# platform_designer_hps_system_hps_0_hps register map
Vendor: default_vendor.com; File version: 0.0
Registers are 32-bit, read-write, reset 0x0 unless marked. A register's access mark holds for its fields unless they carry their own. Offsets are from the block's base; [hi:lo] are bit positions; 'fields as' and 'values as' point back to an identical list.

## l4wd0 — Registers in the L4 Watchdog module
Base 0xFFD02000
Same registers: l4wd1 0xFFD03000
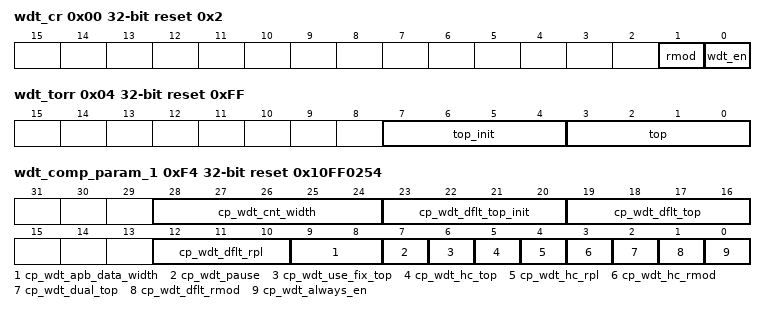
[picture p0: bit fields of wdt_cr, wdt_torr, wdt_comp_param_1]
0x00 wdt_cr reset 0x2 — Contains fields that control operating functions.
  [1] rmod — Selects the output response generated to a timeout.
    0=rst; 1=irqrst
  [0] wdt_en — This bit is used to enable and disable the watchdog. When disabled, the counter does not decrement. Thus, no interrupts or warm reset requests are generated. Once this bit has been enabled, it can only be cleared only by resetting the watchdog.
    0=disabled; 1=enabled
0x04 wdt_torr reset 0xFF — Contains fields that determine the watchdog timeout.
  [7:4] top_init — Used to select the timeout period that the watchdog counter restarts from for the first counter restart (kick). This register should be written after reset and before the watchdog is enabled. A change of the TOP_INIT is seen only once the watchdog has been enabled, and any change after the first kick is not seen as subsequent kicks use the period specified by the TOP bits. The timeout period (in clocks) is: t = 2**(16 + top_init)
    0=timeout64k; 1=timeout128k; 2=timeout256k; 3=timeout512k; 4=timeout1M; 5=timeout2M; 6=timeout4M; 7=timeout8M; 8=timeout16M; 9=timeout32M; 10=timeout64M; 11=timeout128M; 12=timeout256M; 13=timeout512M; 14=timeout1G; 15=timeout2G
  [3:0] top — This field is used to select the timeout period from which the watchdog counter restarts. A change of the timeout period takes effect only after the next counter restart (kick). The timeout period (in clocks) is: t = 2**(16 + top)
    values as top_init
0x08 wdt_ccvr ro reset 0x7FFFFFFF — See Field Description
  [31:0] wdt_ccvr — This register provides the current value of the internal counter.
0x0C wdt_crr wo — Restarts the watchdog.
  [7:0] wdt_crr — This register is used to restart the watchdog counter. As a safety feature to prevent accidental restarts, the kick value of 0x76 must be written. A restart also clears the watchdog interrupt.
    118=kick
0x10 wdt_stat ro — Provides interrupt status
  [0] wdt_stat — Provides the interrupt status of the watchdog.
    1=active; 0=inactive
0x14 wdt_eoi ro — Clears the watchdog interrupt when read.
  [0] wdt_eoi — Clears the watchdog interrupt. This can be used to clear the interrupt without restarting the watchdog counter.
0xE4 cp_wdt_user_top_max ro — This is a constant read-only register that contains encoded information about the component's parameter settings.
  [31:0] cp_wdt_user_top_max — Upper limit of Timeout Period parameters.
0xE8 cp_wdt_user_top_init_max ro — This is a constant read-only register that contains encoded information about the component's parameter settings
  [31:0] cp_wdt_user_top_init_max — Upper limit of Initial Timeout Period parameters.
0xEC cd_wdt_top_rst ro reset 0xFF — This is a constant read-only register that contains encoded information about the component's parameter settings.
  [31:0] cd_wdt_top_rst — Contains the reset value of the WDT_TORR register.
0xF0 cp_wdt_cnt_rst ro reset 0x7FFFFFFF — This is a constant read-only register that contains encoded information about the component's parameter settings.
  [31:0] cp_wdt_cnt_rst — The timeout period range is fixed. The range increments by the power of 2 from 2 to the 16 to 2 to the 31.
0xF4 wdt_comp_param_1 ro reset 0x10FF0254 — This is a constant read-only register that contains encoded information about the component's parameter settings.
  [28:24] cp_wdt_cnt_width — Width of counter in bits less 16.
    16=width32bits
  [23:20] cp_wdt_dflt_top_init — Specifies the initial timeout period that is available directly after reset.
    15=timeout15
  [19:16] cp_wdt_dflt_top — Specifies the timeout period that is available directly after reset.
    15=timeout15
  [12:10] cp_wdt_dflt_rpl — Specifies the reset pulse length in cycles.
    0=pulse2cycles
  [9:8] cp_wdt_apb_data_width — APB Bus Width
    2=width32bits
  [7] cp_wdt_pause — Should specify if the pause input is included or not. However, this field is always hardwired to 0 so you can't figure this out by reading this field. The pause input is included and can be used to pause the watchdog when the MPU is in debug mode.
  [6] cp_wdt_use_fix_top — Specifies if the watchdog uses the pre-defined timeout values or if these were overriden with customer values when the watchdog was configured.
    1=predefined
  [5] cp_wdt_hc_top — Specifies if the timeout period is programmable or hardcoded.
    0=programmable
  [4] cp_wdt_hc_rpl — Specifies if the reset pulse length is programmable or hardcoded.
    1=hardcoded
  [3] cp_wdt_hc_rmod — Specifies if response mode (when counter reaches 0) is programmable or hardcoded.
    0=programmable
  [2] cp_wdt_dual_top — Specifies whether a second timeout period that is used for initialization prior to the first kick is present or not.
    1=dualtop
  [1] cp_wdt_dflt_rmod — Specifies default output response mode after reset.
    0=rstreq
  [0] cp_wdt_always_en — Specifies whether watchdog starts after reset or not.
    0=disabled
0xF8 wdt_comp_version ro reset 0x3130362A
  [31:0] wdt_comp_version — ASCII value for each number in the version, followed by *. For example, 32_30_31_2A represents the version 2.01*.
0xFC wdt_comp_type ro reset 0x44570120
  [31:0] wdt_comp_type — Designware Component Type number = 0x44_57_01_20.
